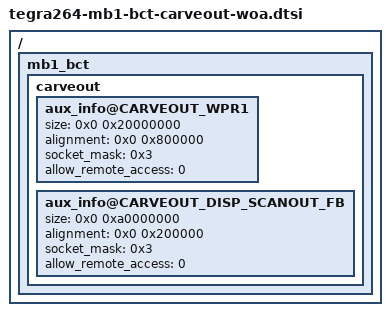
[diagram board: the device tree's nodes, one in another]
/*
 * SPDX-FileCopyrightText: Copyright (c) 2024-2025 NVIDIA CORPORATION & AFFILIATES. All rights reserved.
 * SPDX-License-Identifier: LicenseRef-NvidiaProprietary
 *
 * NVIDIA CORPORATION, its affiliates and licensors retain all intellectual
 * property and proprietary rights in and to this material, related
 * documentation and any modifications thereto. Any use, reproduction,
 * disclosure or distribution of this material and related documentation
 * without an express license agreement from NVIDIA CORPORATION or
 * its affiliates is strictly prohibited.
 */

/* NOTE: This file was auto generated: No manual change must be made in this file */

/ {
	mb1_bct {
		carveout {
			aux_info@CARVEOUT_WPR1 {
				size = <0x0 0x20000000>; // 512MB
				alignment = <0x0 0x800000>; // 8MB
				socket_mask = <0x3>;
				allow_remote_access = <0>;
			};
			aux_info@CARVEOUT_DISP_SCANOUT_FB {
				size = <0x0 0xa0000000>; // 2560MB
				alignment = <0x0 0x200000>; // 2MB
				socket_mask = <0x3>;
				allow_remote_access = <0>;
			};
		};
	};
};
